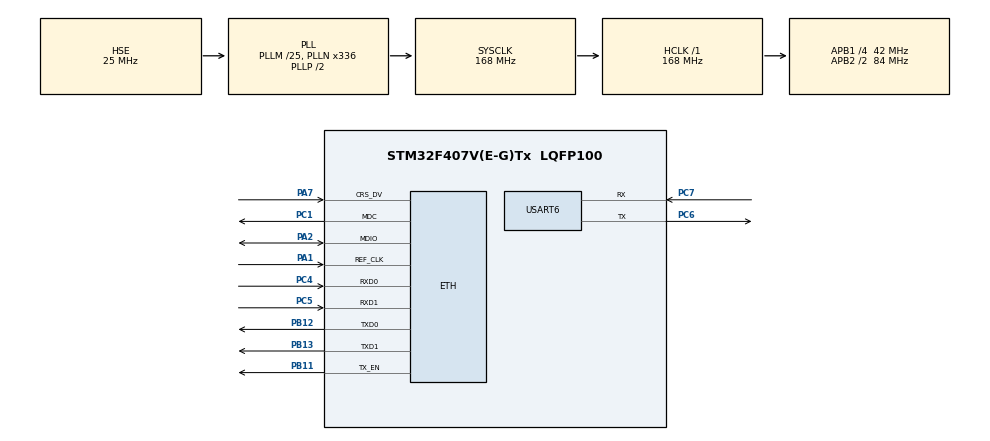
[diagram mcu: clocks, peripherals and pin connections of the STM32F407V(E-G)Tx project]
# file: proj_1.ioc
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ETH.MediaInterface=HAL_ETH_RMII_MODE
ETH.RxMode=ETH_RXINTERRUPT_MODE
Mcu.Family=STM32F4
Mcu.Name=STM32F407V(E-G)Tx
Mcu.Package=LQFP100
NVIC.ETH_IRQn=true\:0\:0\:false\:false\:true\:false\:true\:true\:true
NVIC.ETH_WKUP_IRQn=true\:0\:0\:false\:false\:true\:false\:true\:true\:true
NVIC.PriorityGroup=NVIC_PRIORITYGROUP_4
NVIC.TIM6_DAC_IRQn=true\:15\:0\:false\:false\:true\:false\:false\:true\:true
NVIC.TimeBase=TIM6_DAC_IRQn
NVIC.TimeBaseIP=TIM6
PA1.Mode=RMII
PA1.Signal=ETH_REF_CLK
PA13.Mode=Serial_Wire
PA13.Signal=SYS_JTMS-SWDIO
PA14.Mode=Serial_Wire
PA14.Signal=SYS_JTCK-SWCLK
PA2.Mode=RMII
PA2.Signal=ETH_MDIO
PA7.Mode=RMII
PA7.Signal=ETH_CRS_DV
PB11.Mode=RMII
PB11.Signal=ETH_TX_EN
PB12.Mode=RMII
PB12.Signal=ETH_TXD0
PB13.Mode=RMII
PB13.Signal=ETH_TXD1
PC1.Mode=RMII
PC1.Signal=ETH_MDC
PC4.Mode=RMII
PC4.Signal=ETH_RXD0
PC5.Mode=RMII
PC5.Signal=ETH_RXD1
PC6.Mode=Asynchronous
PC6.Signal=USART6_TX
PC7.Mode=Asynchronous
PC7.Signal=USART6_RX
PH0-OSC_IN.Mode=HSE-External-Oscillator
PH0-OSC_IN.Signal=RCC_OSC_IN
PH1-OSC_OUT.Mode=HSE-External-Oscillator
PH1-OSC_OUT.Signal=RCC_OSC_OUT
ProjectManager.HeapSize=0x2000
ProjectManager.StackSize=0x4000
ProjectManager.TargetToolchain=STM32CubeIDE
RCC.48MHZClocksFreq_Value=84000000
RCC.AHBFreq_Value=168000000
RCC.APB1CLKDivider=RCC_HCLK_DIV4
RCC.APB1Freq_Value=42000000
RCC.APB1TimFreq_Value=84000000
RCC.APB2CLKDivider=RCC_HCLK_DIV2
RCC.APB2Freq_Value=84000000
RCC.APB2TimFreq_Value=168000000
RCC.CortexFreq_Value=168000000
RCC.HCLKFreq_Value=168000000
RCC.HSE_VALUE=25000000
RCC.HSI_VALUE=16000000
RCC.LSE_VALUE=32768
RCC.PLLM=25
RCC.PLLN=336
RCC.PLLSourceVirtual=RCC_PLLSOURCE_HSE
RCC.SYSCLKFreq_VALUE=168000000
RCC.SYSCLKSource=RCC_SYSCLKSOURCE_PLLCLK
RCC.VCOOutputFreq_Value=336000000
STMicroelectronics.X-CUBE-AZRTOS-F4.1.1.0.InterfacesCcNetworkJjCustomOoInterface=true
STMicroelectronics.X-CUBE-AZRTOS-F4.1.1.0.InterfacesCcNetworkJjEthernetOoInterface=true
STMicroelectronics.X-CUBE-AZRTOS-F4.1.1.0.InterfacesCcNetworkJjEthernetOoPhyOoInterface=CustomIiPhyIiInterface
STMicroelectronics.X-CUBE-AZRTOS-F4.1.1.0.NX_APP_MEM_POOL_SIZE=24576
STMicroelectronics.X-CUBE-AZRTOS-F4.1.1.0.NetXDuoCcNetworkJjNetXDuoJjNXOoCore=true
STMicroelectronics.X-CUBE-AZRTOS-F4.1.1.0.TX_APP_MEM_POOL_SIZE=16384
STMicroelectronics.X-CUBE-AZRTOS-F4.1.1.0.ThreadXCcRTOSJjThreadXJjCore=true
STMicroelectronics.X-CUBE-AZRTOS-F4.1.1.0_IsAnAzureRtosMw=true
USART6.VirtualMode=VM_ASYNC
VP_STMicroelectronics.X-CUBE-AZRTOS-F4_VS_NetworkJjInterfaces_2.1.0_1.1.0.Mode=NetworkJjInterfaces
VP_STMicroelectronics.X-CUBE-AZRTOS-F4_VS_NetworkJjNetXDuo_6.1.10_1.1.0.Mode=NetworkJjNetXDuo
VP_STMicroelectronics.X-CUBE-AZRTOS-F4_VS_RTOSJjThreadX_6.1.10_1.1.0.Mode=RTOSJjThreadX
VP_SYS_VS_tim6.Mode=TIM6
board=custom

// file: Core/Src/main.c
/* USER CODE BEGIN Header */
/**
  ******************************************************************************
  * @file           : main.c
  * @brief          : Main program body
  ******************************************************************************
  * @attention
  *
  * Copyright (c) 2025 STMicroelectronics.
  * All rights reserved.
  *
  * This software is licensed under terms that can be found in the LICENSE file
  * in the root directory of this software component.
  * If no LICENSE file comes with this software, it is provided AS-IS.
  *
  ******************************************************************************
  */
/* USER CODE END Header */
#include "app_threadx.h"
#include "main.h"
#include "string.h"

ETH_TxPacketConfig TxConfig;
ETH_DMADescTypeDef  DMARxDscrTab[ETH_RX_DESC_CNT]; /* Ethernet Rx DMA Descriptors */
ETH_DMADescTypeDef  DMATxDscrTab[ETH_TX_DESC_CNT]; /* Ethernet Tx DMA Descriptors */

ETH_HandleTypeDef heth;

UART_HandleTypeDef huart6;

void SystemClock_Config(void);
static void MX_GPIO_Init(void);
static void MX_ETH_Init(void);
static void MX_USART6_UART_Init(void);

/* USER CODE BEGIN 0 */
uint32_t counter_tx = 0;
uint32_t counter_rx = 0;
/* USER CODE END 0 */

int main(void)
{

  /* MCU Configuration--------------------------------------------------------*/

  /* Reset of all peripherals, Initializes the Flash interface and the Systick. */
  HAL_Init();

  /* Configure the system clock */
  SystemClock_Config();

  /* Initialize all configured peripherals */
  MX_GPIO_Init();
  MX_ETH_Init();
  MX_USART6_UART_Init();

  MX_ThreadX_Init();

  /* We should never get here as control is now taken by the scheduler */

  /* Infinite loop */
  while (1)
  {

  }
}

void SystemClock_Config(void)
{
  RCC_OscInitTypeDef RCC_OscInitStruct = {0};
  RCC_ClkInitTypeDef RCC_ClkInitStruct = {0};

  /** Configure the main internal regulator output voltage
  */
  __HAL_RCC_PWR_CLK_ENABLE();
  __HAL_PWR_VOLTAGESCALING_CONFIG(PWR_REGULATOR_VOLTAGE_SCALE1);

  /** Initializes the RCC Oscillators according to the specified parameters
  * in the RCC_OscInitTypeDef structure.
  */
  RCC_OscInitStruct.OscillatorType = RCC_OSCILLATORTYPE_HSE;
  RCC_OscInitStruct.HSEState = RCC_HSE_ON;
  RCC_OscInitStruct.PLL.PLLState = RCC_PLL_ON;
  RCC_OscInitStruct.PLL.PLLSource = RCC_PLLSOURCE_HSE;
  RCC_OscInitStruct.PLL.PLLM = 25;
  RCC_OscInitStruct.PLL.PLLN = 336;
  RCC_OscInitStruct.PLL.PLLP = RCC_PLLP_DIV2;
  RCC_OscInitStruct.PLL.PLLQ = 4;
  if (HAL_RCC_OscConfig(&RCC_OscInitStruct) != HAL_OK)
  {
    Error_Handler();
  }

  /** Initializes the CPU, AHB and APB buses clocks
  */
  RCC_ClkInitStruct.ClockType = RCC_CLOCKTYPE_HCLK|RCC_CLOCKTYPE_SYSCLK
                              |RCC_CLOCKTYPE_PCLK1|RCC_CLOCKTYPE_PCLK2;
  RCC_ClkInitStruct.SYSCLKSource = RCC_SYSCLKSOURCE_PLLCLK;
  RCC_ClkInitStruct.AHBCLKDivider = RCC_SYSCLK_DIV1;
  RCC_ClkInitStruct.APB1CLKDivider = RCC_HCLK_DIV4;
  RCC_ClkInitStruct.APB2CLKDivider = RCC_HCLK_DIV2;

  if (HAL_RCC_ClockConfig(&RCC_ClkInitStruct, FLASH_LATENCY_5) != HAL_OK)
  {
    Error_Handler();
  }
}

static void MX_ETH_Init(void)
{

   static uint8_t MACAddr[6];

  heth.Instance = ETH;
  MACAddr[0] = 0x00;
  MACAddr[1] = 0x80;
  MACAddr[2] = 0xE1;
  MACAddr[3] = 0x00;
  MACAddr[4] = 0x00;
  MACAddr[5] = 0x00;
  heth.Init.MACAddr = &MACAddr[0];
  heth.Init.MediaInterface = HAL_ETH_RMII_MODE;
  heth.Init.TxDesc = DMATxDscrTab;
  heth.Init.RxDesc = DMARxDscrTab;
  heth.Init.RxBuffLen = 1536;

  if (HAL_ETH_Init(&heth) != HAL_OK)
  {
    Error_Handler();
  }

  memset(&TxConfig, 0 , sizeof(ETH_TxPacketConfig));
  TxConfig.Attributes = ETH_TX_PACKETS_FEATURES_CSUM | ETH_TX_PACKETS_FEATURES_CRCPAD;
  TxConfig.ChecksumCtrl = ETH_CHECKSUM_IPHDR_PAYLOAD_INSERT_PHDR_CALC;
  TxConfig.CRCPadCtrl = ETH_CRC_PAD_INSERT;

}

static void MX_USART6_UART_Init(void)
{

  huart6.Instance = USART6;
  huart6.Init.BaudRate = 115200;
  huart6.Init.WordLength = UART_WORDLENGTH_8B;
  huart6.Init.StopBits = UART_STOPBITS_1;
  huart6.Init.Parity = UART_PARITY_NONE;
  huart6.Init.Mode = UART_MODE_TX_RX;
  huart6.Init.HwFlowCtl = UART_HWCONTROL_NONE;
  huart6.Init.OverSampling = UART_OVERSAMPLING_16;
  if (HAL_UART_Init(&huart6) != HAL_OK)
  {
    Error_Handler();
  }

}

static void MX_GPIO_Init(void)
{

  /* GPIO Ports Clock Enable */
  __HAL_RCC_GPIOH_CLK_ENABLE();
  __HAL_RCC_GPIOC_CLK_ENABLE();
  __HAL_RCC_GPIOA_CLK_ENABLE();
  __HAL_RCC_GPIOB_CLK_ENABLE();

}

void HAL_TIM_PeriodElapsedCallback(TIM_HandleTypeDef *htim)
{
  if (htim->Instance == TIM6)
  {
    HAL_IncTick();
  }
}

void Error_Handler(void)
{
  __disable_irq();
  while (1)
  {
  }
}
